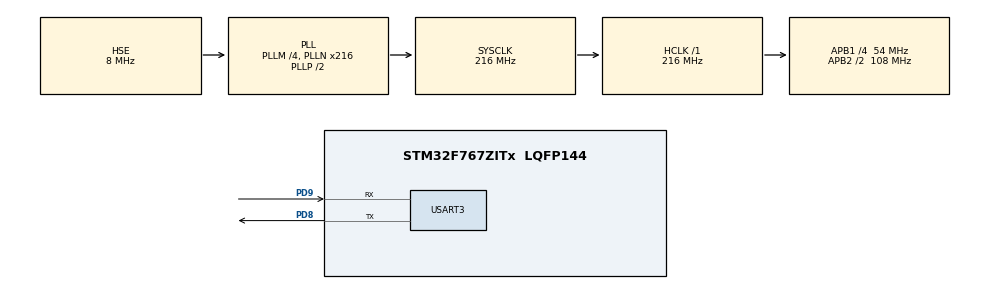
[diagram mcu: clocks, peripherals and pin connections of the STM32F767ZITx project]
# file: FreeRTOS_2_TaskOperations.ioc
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FREERTOS.INCLUDE_vTaskDelayUntil=1
FREERTOS.Tasks01=defaultTask,0,128,StartDefaultTask,Default,NULL,Dynamic,NULL,NULL
FREERTOS.configUSE_NEWLIB_REENTRANT=1
Mcu.Family=STM32F7
Mcu.Name=STM32F767ZITx
Mcu.Package=LQFP144
NVIC.PriorityGroup=NVIC_PRIORITYGROUP_4
NVIC.TIM6_DAC_IRQn=true\:15\:0\:false\:false\:true\:false\:false\:true\:true
NVIC.TimeBase=TIM6_DAC_IRQn
NVIC.TimeBaseIP=TIM6
PD8.Mode=Asynchronous
PD8.Signal=USART3_TX
PD9.Mode=Asynchronous
PD9.Signal=USART3_RX
PH0/OSC_IN.Mode=HSE-External-Oscillator
PH0/OSC_IN.Signal=RCC_OSC_IN
PH1/OSC_OUT.Mode=HSE-External-Oscillator
PH1/OSC_OUT.Signal=RCC_OSC_OUT
ProjectManager.HeapSize=0x200
ProjectManager.StackSize=0x400
ProjectManager.TargetToolchain=STM32CubeIDE
RCC.AHBFreq_Value=216000000
RCC.APB1CLKDivider=RCC_HCLK_DIV4
RCC.APB1Freq_Value=54000000
RCC.APB1TimFreq_Value=108000000
RCC.APB2CLKDivider=RCC_HCLK_DIV2
RCC.APB2Freq_Value=108000000
RCC.APB2TimFreq_Value=216000000
RCC.CortexFreq_Value=216000000
RCC.HCLKFreq_Value=216000000
RCC.HSE_VALUE=8000000
RCC.HSI_VALUE=16000000
RCC.LSE_VALUE=32768
RCC.PLLM=4
RCC.PLLN=216
RCC.PLLSourceVirtual=RCC_PLLSOURCE_HSE
RCC.SYSCLKFreq_VALUE=216000000
RCC.SYSCLKSource=RCC_SYSCLKSOURCE_PLLCLK
RCC.USBFreq_Value=216000000
RCC.VCOOutputFreq_Value=432000000
USART3.VirtualMode-Asynchronous=VM_ASYNC
VP_FREERTOS_VS_CMSIS_V1.Mode=CMSIS_V1
VP_SYS_VS_tim6.Mode=TIM6
board=custom

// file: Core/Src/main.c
/* USER CODE BEGIN Header */
/**
  ******************************************************************************
  * @file           : main.c
  * @brief          : Main program body
  ******************************************************************************
  * @attention
  *
  * Copyright (c) 2022 STMicroelectronics.
  * All rights reserved.
  *
  * This software is licensed under terms that can be found in the LICENSE file
  * in the root directory of this software component.
  * If no LICENSE file comes with this software, it is provided AS-IS.
  *
  ******************************************************************************
  */
/* USER CODE END Header */
#include "main.h"
#include "cmsis_os.h"

/* USER CODE BEGIN Includes */
#include <stdio.h>
#include <string.h>
/* USER CODE END Includes */

UART_HandleTypeDef huart3;

osThreadId defaultTaskHandle;
/* USER CODE BEGIN PV */

osThreadId task2Handler;
uint8_t cou_task2 = 0;

/* USER CODE END PV */

void SystemClock_Config(void);
static void MX_GPIO_Init(void);
static void MX_USART3_UART_Init(void);
void StartDefaultTask(void const * argument);

/* USER CODE BEGIN PFP */
void StartTask2Handler(void const * argument);
/* USER CODE END PFP */

int main(void)
{

  /* MCU Configuration--------------------------------------------------------*/

  /* Reset of all peripherals, Initializes the Flash interface and the Systick. */
  HAL_Init();

  /* Configure the system clock */
  SystemClock_Config();

  /* Initialize all configured peripherals */
  MX_GPIO_Init();
  MX_USART3_UART_Init();
  /* USER CODE BEGIN 2 */

  // sending data through USART at the beginning of Programm
  char stri[] = "Programm started!!!\n\r";
  HAL_UART_Transmit(&huart3, (uint8_t*)stri, strlen(stri), HAL_MAX_DELAY); //HAL_MAX_DELAY -> 0xFFFFFFFFU

  /* USER CODE END 2 */

  /* Create the thread(s) */
  /* definition and creation of defaultTask */
  osThreadDef(defaultTask, StartDefaultTask, osPriorityNormal, 0, 128);
  defaultTaskHandle = osThreadCreate(osThread(defaultTask), NULL);

  /* USER CODE BEGIN RTOS_THREADS */
  /* add threads, ... */

  // define the thread
  osThreadDef(task2, StartTask2Handler, osPriorityAboveNormal, 0, 128);
  // create thread adn assign ID
  task2Handler = osThreadCreate(osThread(task2), NULL);

  /* USER CODE END RTOS_THREADS */

  /* Start scheduler */
  osKernelStart();

  /* We should never get here as control is now taken by the scheduler */
  /* Infinite loop */
  while (1)
  {

  }
}

void SystemClock_Config(void)
{
  RCC_OscInitTypeDef RCC_OscInitStruct = {0};
  RCC_ClkInitTypeDef RCC_ClkInitStruct = {0};

  /** Configure the main internal regulator output voltage
  */
  __HAL_RCC_PWR_CLK_ENABLE();
  __HAL_PWR_VOLTAGESCALING_CONFIG(PWR_REGULATOR_VOLTAGE_SCALE1);

  /** Initializes the RCC Oscillators according to the specified parameters
  * in the RCC_OscInitTypeDef structure.
  */
  RCC_OscInitStruct.OscillatorType = RCC_OSCILLATORTYPE_HSE;
  RCC_OscInitStruct.HSEState = RCC_HSE_ON;
  RCC_OscInitStruct.PLL.PLLState = RCC_PLL_ON;
  RCC_OscInitStruct.PLL.PLLSource = RCC_PLLSOURCE_HSE;
  RCC_OscInitStruct.PLL.PLLM = 4;
  RCC_OscInitStruct.PLL.PLLN = 216;
  RCC_OscInitStruct.PLL.PLLP = RCC_PLLP_DIV2;
  RCC_OscInitStruct.PLL.PLLQ = 2;
  RCC_OscInitStruct.PLL.PLLR = 2;
  if (HAL_RCC_OscConfig(&RCC_OscInitStruct) != HAL_OK)
  {
    Error_Handler();
  }

  /** Activate the Over-Drive mode
  */
  if (HAL_PWREx_EnableOverDrive() != HAL_OK)
  {
    Error_Handler();
  }

  /** Initializes the CPU, AHB and APB buses clocks
  */
  RCC_ClkInitStruct.ClockType = RCC_CLOCKTYPE_HCLK|RCC_CLOCKTYPE_SYSCLK
                              |RCC_CLOCKTYPE_PCLK1|RCC_CLOCKTYPE_PCLK2;
  RCC_ClkInitStruct.SYSCLKSource = RCC_SYSCLKSOURCE_PLLCLK;
  RCC_ClkInitStruct.AHBCLKDivider = RCC_SYSCLK_DIV1;
  RCC_ClkInitStruct.APB1CLKDivider = RCC_HCLK_DIV4;
  RCC_ClkInitStruct.APB2CLKDivider = RCC_HCLK_DIV2;

  if (HAL_RCC_ClockConfig(&RCC_ClkInitStruct, FLASH_LATENCY_7) != HAL_OK)
  {
    Error_Handler();
  }
}

static void MX_USART3_UART_Init(void)
{

  huart3.Instance = USART3;
  huart3.Init.BaudRate = 115200;
  huart3.Init.WordLength = UART_WORDLENGTH_8B;
  huart3.Init.StopBits = UART_STOPBITS_1;
  huart3.Init.Parity = UART_PARITY_NONE;
  huart3.Init.Mode = UART_MODE_TX_RX;
  huart3.Init.HwFlowCtl = UART_HWCONTROL_NONE;
  huart3.Init.OverSampling = UART_OVERSAMPLING_16;
  huart3.Init.OneBitSampling = UART_ONE_BIT_SAMPLE_DISABLE;
  huart3.AdvancedInit.AdvFeatureInit = UART_ADVFEATURE_NO_INIT;
  if (HAL_UART_Init(&huart3) != HAL_OK)
  {
    Error_Handler();
  }

}

static void MX_GPIO_Init(void)
{

  /* GPIO Ports Clock Enable */
  __HAL_RCC_GPIOH_CLK_ENABLE();
  __HAL_RCC_GPIOD_CLK_ENABLE();

}

/* USER CODE BEGIN 4 */

void StartTask2Handler(void const * argument){
	while(1){
		// sending data through USART
		char buffer[50];
		snprintf(buffer, 50, "Counter value from StartTask2Handler: %d \n\r", cou_task2++);
		HAL_UART_Transmit(&huart3, (uint8_t*)buffer, strlen(buffer), HAL_MAX_DELAY);
		osDelay(1000);

		// suspending defaultTaskHandle at %10
		if (cou_task2%10 == 0){
			char stri[] = "{From StartTask2Handler} Suspending defaultTaskHandle.\n\r";
		    HAL_UART_Transmit(&huart3, (uint8_t*)stri, strlen(stri), HAL_MAX_DELAY); //HAL_MAX_DELAY -> 0xFFFFFFFFU
			osThreadSuspend(defaultTaskHandle);
		}
		// resuming defaultTaskHandle at %10=4
		if (cou_task2%10 == 4){
			char stri[] = "{From StartTask2Handler} Resuming defaultTaskHandle.\n\r";
			HAL_UART_Transmit(&huart3, (uint8_t*)stri, strlen(stri), HAL_MAX_DELAY); //HAL_MAX_DELAY -> 0xFFFFFFFFU
			osThreadResume(defaultTaskHandle);
		}

		/* example for terminating thread(s)
		if (cou_task2 == 20){
			osThreadTerminate(defaultTaskHandle);
		}
		if (cou_task2 == 30){
			osThreadTerminate(task2Handler);
		}
		*/

		// delaying the current task for 3 sec on cou_task2=20
		if (cou_task2 == 20){
			uint32_t PreviousWakeTime = osKernelSysTick();
			osDelayUntil(&PreviousWakeTime, 3000); // inactive for 3 sec
		}
	}
}

/* USER CODE END 4 */

void StartDefaultTask(void const * argument)
{
  /* USER CODE BEGIN 5 */
  /* Infinite loop */
  for(;;)
  {
	  // sending data through USART at the beginning of Programm
	  char stri[] = "Msg from StartDefaultTask.\n\r";
	  HAL_UART_Transmit(&huart3, (uint8_t*)stri, strlen(stri), HAL_MAX_DELAY); //HAL_MAX_DELAY -> 0xFFFFFFFFU
      osDelay(1000);
  }
  /* USER CODE END 5 */
}

void HAL_TIM_PeriodElapsedCallback(TIM_HandleTypeDef *htim)
{
  if (htim->Instance == TIM6) {
    HAL_IncTick();
  }
}

void Error_Handler(void)
{
  __disable_irq();
  while (1)
  {
  }
}
